# CY8C5868AXI_LP035 register map
File version: 0.1
Registers are 8-bit, read-write, no defined reset value unless marked. A register's access mark holds for its fields unless they carry their own. Offsets are from the block's base; [hi:lo] are bit positions; {n}, {i} and the like mark numbered series; 'fields as' and 'values as' point back to an identical list.

## Status_Reg_MOTORS
Base 0x4000656B
0x00 Status_Reg_MOTORS_STATUS_REG
0x20 Status_Reg_MOTORS_MASK_REG
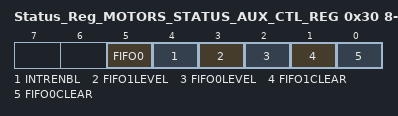
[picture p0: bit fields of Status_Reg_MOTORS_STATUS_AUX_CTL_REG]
0x30 Status_Reg_MOTORS_STATUS_AUX_CTL_REG
  [5] FIFO0 — FIFO0 clear
    1=ENABLED (Enable counter); 0=DISABLED (Disable counter)
  [4] INTRENBL — Enables or disables the Interrupt
    1=ENABLED (Interrupt enabled); 0=DISABLED (Interrupt disabled)
  [3] FIFO1LEVEL — FIFO level
    1=ENABLED (FIFO LVL: input mode: FIFO at least 1/2 empty; output mode: FIFO at least 1/2 full); 0=DISABLED (FIFO LVL: input mode: FIFO not full; output mode: FIFO not empty)
  [2] FIFO0LEVEL — FIFO level
    values as FIFO1LEVEL
  [1] FIFO1CLEAR — FIFO clear
    1=ENABLED (Clear FIFO state); 0=DISABLED (Normal FIFO operation)
  [0] FIFO0CLEAR — FIFO clear
    values as FIFO1CLEAR

## Status_Reg_SYS
Base 0x40006566
Registers as Status_Reg_MOTORS (with Status_Reg_MOTORS read as Status_Reg_SYS).

## Status_Reg_BUTTON
Base 0x40006463
Registers as Status_Reg_MOTORS (with Status_Reg_MOTORS read as Status_Reg_BUTTON).

## Control_Reg_WS
Base 0x40006574
0x00 Control_Reg_WS_CONTROL_REG

## Control_Reg_LORA_RESET
Base 0x40006472
Registers as Control_Reg_WS (with Control_Reg_WS read as Control_Reg_LORA_RESET).

## Control_Reg_LORA
Base 0x40006575
Registers as Control_Reg_WS (with Control_Reg_WS read as Control_Reg_LORA).

## Control_Reg_SYS
Base 0x40006579
Registers as Control_Reg_WS (with Control_Reg_WS read as Control_Reg_SYS).

## Control_Reg_LED
Base 0x4000647A
Registers as Control_Reg_WS (with Control_Reg_WS read as Control_Reg_LED).

## Control_Reg_MOTOR
Base 0x4000657A
Registers as Control_Reg_WS (with Control_Reg_WS read as Control_Reg_MOTOR).

## Control_Reg_BUZ
Base 0x40006474
Registers as Control_Reg_WS (with Control_Reg_WS read as Control_Reg_BUZ).

## WaveDAC8_BuffAmp
Base 0x400043A4
0x00 PM_ACT_CFG4 — Active Power Mode Configuration Register 4
  [3:0] EN_OPAMP — Enables subsystems during active power mode
    0=Blk_0 (Enables analog linear output buffer for Opamp block 0); 2=Blk_1 (Enables analog linear output buffer for Opamp block 1); 4=Blk_2 (Enables analog linear output buffer for Opamp block 2); 8=Blk_3 (Enables analog linear output buffer for Opamp block 3)
0x10 PM_STBY_CFG4 — Standby Power Mode Configuration Register 4
  [3:0] EN_OPAMP — Enables subsystems during standby power mode
    values as PM_ACT_CFG4.EN_OPAMP
0x280 OPAMP__TR0 — Analog Output Buffer Trim Register 0
  [4:0] offset_trim — Offset Trim: 420uV typical step size; +/- 6.8mV offset trimmable range
0x281 OPAMP__TR1 — Analog Output Buffer Trim Register 1
0x14B8 OPAMP__CR — Analog Output Buffer Configuration Register
  [1:0] pwr_mode — Power Mode
    0=Default_Fast (Default Power mode Fast); 1=Slow (Power Mode Slow); 2=Medium (Power Mode Medium); 3=Fast (Power Mode Fast)
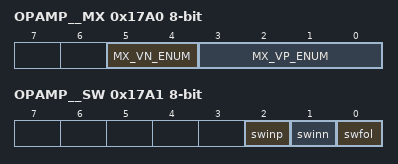
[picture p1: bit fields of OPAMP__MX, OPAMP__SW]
0x17A0 OPAMP__MX — Analog Buffer Input Selection Register
  [5:4] MX_VN_ENUM — MUX select VN (Negative terminal input)
    0=OPAMP0_MX_VN_DEFAULT (Default - Not Connected (NC)); 1=OPAMP0_MX_VN_AG4 (MUX Selection AGL(4)); 2=OPAMP0_MX_VN_AG6 (MUX Selection AGL(6)); 3=OPAMP0_MX_VN_0x3 (Reserved (NC))
  [3:0] MX_VP_ENUM — MUX select VP (Positive terminal input)
    0=OPAMP0_MX_VP_DEFAULT (Default - Not Connected (NC)); {v}=OPAMP0_MX_VP_AG{v+3} (MUX Selection AGL({v+3})) (v=1..4); {v}=OPAMP0_MX_VP_ABUS{v-5} (MUX Selection ABUSL({v-5})) (v=5..8); 9=OPAMP0_MX_VP_VREF (MUX Selection: OPAMP Voltage Reference); {v}=OPAMP0_MX_VP_H_{0x0+v} (Reserved (NC)) (v=10..15)
0x17A1 OPAMP__SW — Analog Buffer Routing Switch Register
  [2] swinp — Switch Enable Positive Input
  [1] swinn — Switch Enable Negative Input
  [0] swfol — Switch Enable Follow
